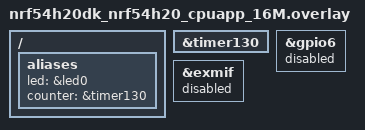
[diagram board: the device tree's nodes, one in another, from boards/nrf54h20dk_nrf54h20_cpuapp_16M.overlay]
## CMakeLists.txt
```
#
# Copyright (c) 2024 Nordic Semiconductor
#
# SPDX-License-Identifier: LicenseRef-Nordic-5-Clause
#

cmake_minimum_required(VERSION 3.13.1)
find_package(Zephyr REQUIRED HINTS $ENV{ZEPHYR_BASE})
zephyr_include_directories(include)

project(timer_waiting)

target_sources(app PRIVATE src/driver_test.c)
```

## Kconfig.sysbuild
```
#
# Copyright (c) 2024 Nordic Semiconductor ASA
#
# SPDX-License-Identifier: LicenseRef-Nordic-5-Clause
#

if SUPPORT_NETCORE

choice NETCORE
	default NETCORE_REMOTE_SLEEP_FOREVER if SOC_NRF54H20_CPUAPP
	default NETCORE_NONE

config NETCORE_REMOTE_SLEEP_FOREVER
	bool "Remote sleep forever image"

endchoice

config NETCORE_IMAGE_NAME
	default "remote_sleep_forever" if NETCORE_REMOTE_SLEEP_FOREVER

config NETCORE_IMAGE_PATH
	default "$(ZEPHYR_NRF_MODULE_DIR)/tests/benchmarks/power_consumption/common/remote_sleep_forever" if NETCORE_REMOTE_SLEEP_FOREVER

endif # SUPPORT_NETCORE

source "share/sysbuild/Kconfig"
```

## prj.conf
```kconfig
# Drivers and peripherals
CONFIG_COUNTER=y

# Enable runtime power management for peripheral
CONFIG_PM_DEVICE=y
CONFIG_PM_DEVICE_RUNTIME=y

CONFIG_PM=y
CONFIG_POWEROFF=y
CONFIG_CONSOLE=n
CONFIG_UART_CONSOLE=n
CONFIG_SERIAL=n
CONFIG_BOOT_BANNER=n
CONFIG_NCS_BOOT_BANNER=n
```

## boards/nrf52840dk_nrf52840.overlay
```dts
/ {
	aliases {
		counter = &timer0;
	};
};

&timer0 {
	status = "okay";
};
```

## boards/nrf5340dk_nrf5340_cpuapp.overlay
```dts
/ {
	aliases {
		counter = &timer0;
	};
};

&timer0 {
	status = "okay";
};

&vregmain {
	regulator-initial-mode = <NRF5X_REG_MODE_LDO>;
};
```

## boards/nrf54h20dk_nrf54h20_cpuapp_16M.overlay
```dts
/* TIMER130, 16MHz */

/ {
	aliases {
		led = &led0;
		/delete-property/ led1;
		counter = &timer130;
	};
};

&timer130 {
	status = "okay";
};

/delete-node/ &led1;

&gpio6 {
	status = "disabled";
};

&exmif {
	status = "disabled";
};
```

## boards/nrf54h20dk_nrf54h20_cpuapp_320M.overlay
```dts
/* TIMER120, 320MHz */

/ {
	aliases {
		led = &led0;
		/delete-property/ led1;
		counter = &timer120;
	};
};

&timer120 {
	status = "okay";
};

/delete-node/ &led1;

&gpio6 {
	status = "disabled";
};

&exmif {
	status = "disabled";
};
```

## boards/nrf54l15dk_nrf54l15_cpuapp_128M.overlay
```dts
/* TIMER00, 128MHz */

/ {
	aliases {
		led = &button3;
		counter = &timer00;
	};
};

&timer00 {
	status = "okay";
};
```

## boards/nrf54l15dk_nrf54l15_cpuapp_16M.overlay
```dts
/* TIMER20, 16MHz */

/ {
	aliases {
		led = &button3;
		counter = &timer20;
	};
};

&timer20 {
	status = "okay";
};
```

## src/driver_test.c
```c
/*
 * Copyright (c) 2024 Nordic Semiconductor ASA
 *
 * SPDX-License-Identifier: LicenseRef-Nordic-5-Clause
 */

#include <zephyr/kernel.h>
#include <zephyr/drivers/counter.h>

#define ALARM_CHANNEL_ID (0)
const struct device *const counter_dev = DEVICE_DT_GET(DT_ALIAS(counter));
struct counter_alarm_cfg counter_cfg;

void counter_handler(const struct device *counter_dev, uint8_t chan_id,
	uint32_t ticks, void *user_data)
{
	k_busy_wait(500000);
	counter_stop(counter_dev);
}

int main(void)
{
	while (1) {
		k_msleep(1500);
		counter_start(counter_dev);

		counter_cfg.flags = 0;
		counter_cfg.ticks = counter_us_to_ticks(counter_dev, 1000000UL);
		counter_cfg.callback = counter_handler;
		counter_cfg.user_data = &counter_cfg;

		counter_set_channel_alarm(counter_dev, ALARM_CHANNEL_ID, &counter_cfg);
		k_msleep(1500);
	}

	return 0;
}
```
